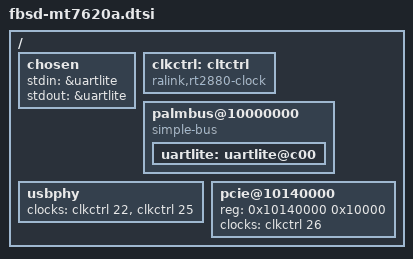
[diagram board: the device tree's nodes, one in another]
/* $FreeBSD$ */

/ {

	/*
	 * FreeBSD's stdin and stdout, so we can have a console
	 */
	chosen {
		stdin = &uartlite;
		stdout = &uartlite;
	};

	/*
	 * OpenWRT doesn't define a clock controller, but we currently need one
	 */
	clkctrl: cltctrl {
		compatible = "ralink,rt2880-clock";
		#clock-cells = <1>;
	};

	palmbus@10000000 {
		/*
		 * Make palmbus compatible to our simplebus
		 */
		compatible = "simple-bus";

		/*
		 * Reference uartlite@c00 as uartlite, so we can address it
		 * within the chosen node above
		 */
		uartlite: uartlite@c00 {};
	};

	usbphy: usbphy {
		clocks = <&clkctrl 22 &clkctrl 25>;
		clock-names = "host", "device";
	};

	pcie@10140000 {
		/*
		 * Our driver is different that OpenWRT's, so we need slightly
		 * different values for the reg property
		 */
		reg = <0x10140000 0x10000>;

		/*
		 * Also, we need resets and clocks defined, so we can properly
		 * initialize the PCIe
		 */
		clocks = <&clkctrl 26>;
	};
};
